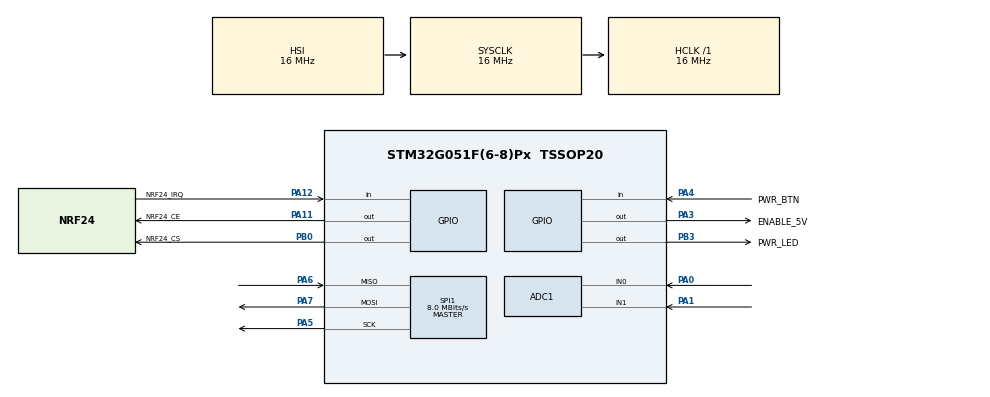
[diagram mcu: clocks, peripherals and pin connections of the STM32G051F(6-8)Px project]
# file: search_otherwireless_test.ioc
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ADC1.Channel-0\#ChannelRegularConversion=ADC_CHANNEL_0
ADC1.NbrOfConversionFlag=1
ADC1.Rank-0\#ChannelRegularConversion=1
ADC1.SamplingTime-0\#ChannelRegularConversion=ADC_SAMPLINGTIME_COMMON_1
ADC1.SelectedChannel=ADC_CHANNEL_0|ADC_CHANNEL_1
ADC1.master=1
Mcu.Family=STM32G0
Mcu.Name=STM32G051F(6-8)Px
Mcu.Package=TSSOP20
PA0.Mode=IN0
PA0.Signal=ADC1_IN0
PA1.Mode=IN1
PA1.Signal=ADC1_IN1
PA11\ [PA9].GPIO_Label=NRF24_CE
PA11\ [PA9].Signal=GPIO_Output
PA12\ [PA10].GPIO_Label=NRF24_IRQ
PA12\ [PA10].Signal=GPIO_Input
PA13.Mode=Serial_Wire
PA13.Signal=SYS_SWDIO
PA14-BOOT0.Mode=Serial_Wire
PA14-BOOT0.Signal=SYS_SWCLK
PA14-BOOT0__PA15.StandardMode=true
PA3.GPIO_Label=ENABLE_5V
PA3.Signal=GPIO_Output
PA4.GPIO_Label=PWR_BTN
PA4.Signal=GPIO_Input
PA5.Mode=Full_Duplex_Master
PA5.Signal=SPI1_SCK
PA6.Mode=Full_Duplex_Master
PA6.Signal=SPI1_MISO
PA7.Mode=Full_Duplex_Master
PA7.Signal=SPI1_MOSI
PB0.GPIO_Label=NRF24_CS
PB0.Signal=GPIO_Output
PB0__PB1__PB2__PA8.StandardMode=true
PB3.GPIO_Label=PWR_LED
PB3.GPIO_ModeDefaultOutputPP=GPIO_MODE_OUTPUT_PP
PB3.Signal=GPIO_Output
PB3__PB4__PB5__PB6.StandardMode=true
PB7__PB8.StandardMode=true
PC14-OSC32_IN\ (PC14)__PB9.StandardMode=true
ProjectManager.HeapSize=0x200
ProjectManager.StackSize=0x400
ProjectManager.TargetToolchain=STM32CubeIDE
RCC.AHBFreq_Value=16000000
RCC.CortexFreq_Value=16000000
RCC.EXTERNAL_CLOCK_VALUE=48000
RCC.HCLKFreq_Value=16000000
RCC.HSE_VALUE=8000000
RCC.HSI_VALUE=16000000
RCC.LSE_VALUE=32768
RCC.SYSCLKFreq_VALUE=16000000
RCC.VCOOutputFreq_Value=128000000
SPI1.CalculateBaudRate=8.0 MBits/s
SPI1.Direction=SPI_DIRECTION_2LINES
SPI1.Mode=SPI_MODE_MASTER
SPI1.VirtualType=VM_MASTER
VP_SYS_VS_DBSignals.Mode=DisableDeadBatterySignals
board=custom

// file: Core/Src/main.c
/* USER CODE BEGIN Header */
/**
  ******************************************************************************
  * @file           : main.c
  * @brief          : Main program body
  ******************************************************************************
  * @attention
  *
  * Copyright (c) 2024 STMicroelectronics.
  * All rights reserved.
  *
  * This software is licensed under terms that can be found in the LICENSE file
  * in the root directory of this software component.
  * If no LICENSE file comes with this software, it is provided AS-IS.
  *
  ******************************************************************************
  */
/* USER CODE END Header */
#include "main.h"
#include "adc.h"
#include "spi.h"
#include "gpio.h"

/* USER CODE BEGIN Includes */
#include "nrf24l01p.h"
/* USER CODE END Includes */

void SystemClock_Config(void);

int main(void)
{

  /* MCU Configuration--------------------------------------------------------*/

  /* Reset of all peripherals, Initializes the Flash interface and the Systick. */
  HAL_Init();

  /* Configure the system clock */
  SystemClock_Config();

  /* Initialize all configured peripherals */
  MX_GPIO_Init();
  MX_ADC1_Init();
  MX_SPI1_Init();
  /* USER CODE BEGIN 2 */

  uint8_t rx_data[NRF24L01P_PAYLOAD_LENGTH] = { 0, };
  nrf24l01p_rx_init(2500, _1Mbps);
  /* USER CODE END 2 */

  /* Infinite loop */
  /* USER CODE BEGIN WHILE */
  while (1)
  {

	if (!HAL_GPIO_ReadPin(NRF24_IRQ_GPIO_Port,NRF24_IRQ_Pin)) {
		nrf24l01p_rx_receive(rx_data); // read data
	}
	HAL_Delay(100);
    /* USER CODE END WHILE */

  }
}

void SystemClock_Config(void)
{
  RCC_OscInitTypeDef RCC_OscInitStruct = {0};
  RCC_ClkInitTypeDef RCC_ClkInitStruct = {0};

  /** Configure the main internal regulator output voltage
  */
  HAL_PWREx_ControlVoltageScaling(PWR_REGULATOR_VOLTAGE_SCALE1);

  /** Initializes the RCC Oscillators according to the specified parameters
  * in the RCC_OscInitTypeDef structure.
  */
  RCC_OscInitStruct.OscillatorType = RCC_OSCILLATORTYPE_HSI;
  RCC_OscInitStruct.HSIState = RCC_HSI_ON;
  RCC_OscInitStruct.HSIDiv = RCC_HSI_DIV1;
  RCC_OscInitStruct.HSICalibrationValue = RCC_HSICALIBRATION_DEFAULT;
  RCC_OscInitStruct.PLL.PLLState = RCC_PLL_NONE;
  if (HAL_RCC_OscConfig(&RCC_OscInitStruct) != HAL_OK)
  {
    Error_Handler();
  }

  /** Initializes the CPU, AHB and APB buses clocks
  */
  RCC_ClkInitStruct.ClockType = RCC_CLOCKTYPE_HCLK|RCC_CLOCKTYPE_SYSCLK
                              |RCC_CLOCKTYPE_PCLK1;
  RCC_ClkInitStruct.SYSCLKSource = RCC_SYSCLKSOURCE_HSI;
  RCC_ClkInitStruct.AHBCLKDivider = RCC_SYSCLK_DIV1;
  RCC_ClkInitStruct.APB1CLKDivider = RCC_HCLK_DIV1;

  if (HAL_RCC_ClockConfig(&RCC_ClkInitStruct, FLASH_LATENCY_0) != HAL_OK)
  {
    Error_Handler();
  }
}

void Error_Handler(void)
{
  __disable_irq();
  while (1)
  {
  }
}
